# SAM9X75D1GN2 device description
Architecture: ARM926EJ-S; Family: SAM9; Series: SAM9X7
Registers are 32-bit, read-write, reset 0x0 unless marked. A register's access mark holds for its fields unless they carry their own. Offsets are from the block's base; [hi:lo] are bit positions.

## TRNG — True Random Number Generator
Instances: TRNG 0xF0030000
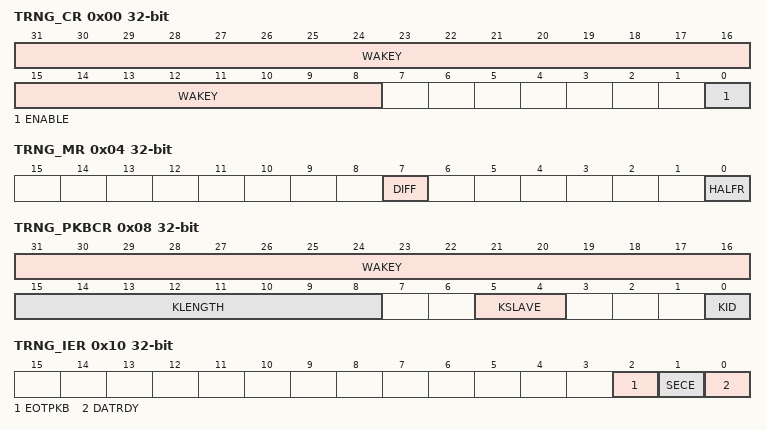
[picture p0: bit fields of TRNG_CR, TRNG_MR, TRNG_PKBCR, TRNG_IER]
0x00 TRNG_CR wo reset not defined — Control Register
  [31:8] WAKEY — Register Write Access Key
    0x524E47=PASSWD (Writing any other value in this field aborts the write operation.)
  [0] ENABLE — Enable TRNG to Provide Random Values
    0=Disables the TRNG if 0x524E47 ("RNG" in ASCII) is written in WAKEY field at the same time; 1=Enables the TRNG if 0x524E47 ("RNG" in ASCII) is written in WAKEY field at the same time
0x04 TRNG_MR — Mode Register
  [7] DIFF — Minimum Hamming Distance
    0=DISABLED (Delivers a new random sample without condition with the previous sample (unless HD=1).)
  [0] HALFR — Half Rate Enable
    0=DISABLED (Maximum stream rate provided (1 sample every 84 MCK clock cycles).); 1=ENABLED (Half maximum stream rate provided if the peripheral clock frequency is above 100 MHz (1 sample every 168 MCK clock cycles).)
0x08 TRNG_PKBCR wo reset not defined — Private Key Bus Control Register
  [31:16] WAKEY — Register Write Access Key
    0x524B=PASSWD (Writing any other value in this field aborts the write operation.)
  [15:8] KLENGTH — Key Length
  [5:4] KSLAVE — Key Bus Client
    0=TDES_ID; 1=AES_ID; 2=OTPC_ID
  [0] KID — Key ID (Must be Always Written to 0)
0x10 TRNG_IER wo reset not defined (atomic set of TRNG_IMR) — Interrupt Enable Register
  [all] fields
    0=No effect; 1=Enables the corresponding interrupt
  [2] EOTPKB — End Of Transfer on Private Key Bus Interrupt Enable
  [1] SECE — Security and/or Safety Event Interrupt Enable
  [0] DATRDY — Data Ready Interrupt Enable
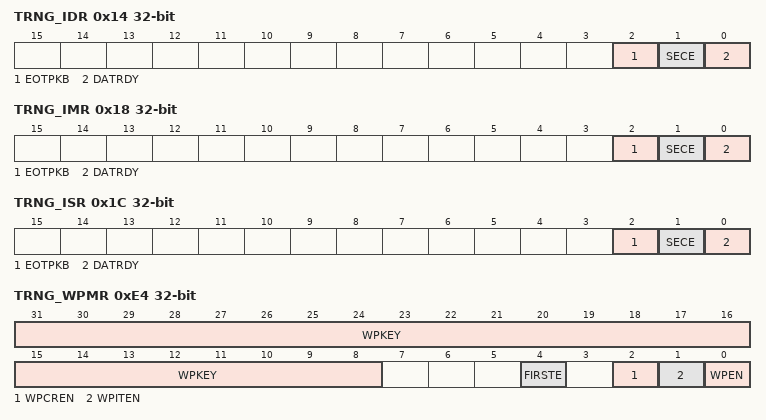
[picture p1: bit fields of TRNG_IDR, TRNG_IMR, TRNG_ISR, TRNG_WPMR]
0x14 TRNG_IDR wo reset not defined (atomic clear of TRNG_IMR) — Interrupt Disable Register
  [all] fields
    0=No effect; 1=Disables the corresponding interrupt
  [2] EOTPKB — End Of Transfer on Private Key Bus Interrupt Disable
  [1] SECE — Security and/or Safety Event Interrupt Disable
  [0] DATRDY — Data Ready Interrupt Disable
0x18 TRNG_IMR ro — Interrupt Mask Register
  [all] fields
    0=The corresponding interrupt is not enabled; 1=The corresponding interrupt is enabled
  [2] EOTPKB — End Of Transfer on Private Key Bus Interrupt Mask
  [1] SECE — Security and/or Safety Event Interrupt Mask
  [0] DATRDY — Data Ready Interrupt Mask
0x1C TRNG_ISR ro — Interrupt Status Register
  [2] EOTPKB — End Of Transfer on Private Key Bus (cleared on read)
    0=No private key bus transfer has ended since the last read of the Interrupt Status register; 1=The private key bus transfer has ended
  [1] SECE — Security and/or Safety Event (cleared on read)
    0=No safety or security event occurred since the last read of the Interrupt Status Register; 1=One or more safety or security event occurred since the last read of TRNG_ISR. For details on the event, see TRNG Write Protection Status Register.
  [0] DATRDY — Data Ready (cleared on read)
    0=Output data is not valid or TRNG is disabled; 1=New random value has been completed since the last read of TRNG_ISR
0x50 TRNG_ODATA ro — Output Data Register
  [31:0] ODATA — Output Data
0xE4 TRNG_WPMR — Write Protection Mode Register
  [31:8] WPKEY — Write Protection Key
    0x524E47=PASSWD (Writing any other value in this field aborts the write operation of bits WPEN, WPITEN and WPCREN. Always reads as 0.)
  [4] FIRSTE — First Error Report Enable
    0=The last write protection violation source is reported in TRNG_WPSR.WPVSRC and the last software control error type is reported in TRNG_WPSR.SWETYP. The TRNG_ISR.SECE flag is set at the first error occurrence within a series.; 1=Only the first write protection violation source is reported in TRNG_WPSR.WPVSRC and only the first software control error type is reported in TRNG_WPSR.SWETYP. The TRNG_ISR.SECE flag is set at the first error occurrence within a series.
  [2] WPCREN — Write Protection Control Enable
    0=Disables the write protection on control register if WPKEY corresponds to 0x524E47 ("RNG" in ASCII); 1=Enables the write protection on control register if WPKEY corresponds to 0x524E47 ("RNG" in ASCII)
  [1] WPITEN — Write Protection Interrupt Enable
    0=Disables the write protection on interrupt registers if WPKEY corresponds to 0x524E47 ("RNG" in ASCII); 1=Enables the write protection on interrupt registers if WPKEY corresponds to 0x524E47 ("RNG" in ASCII)
  [0] WPEN — Write Protection Enable
    0=Disables the write protection if WPKEY corresponds to 0x524E47 ("RNG" in ASCII); 1=Enables the write protection if WPKEY corresponds to 0x524E47 ("RNG" in ASCII)
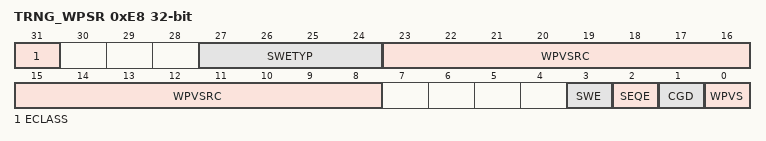
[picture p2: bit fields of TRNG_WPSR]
0xE8 TRNG_WPSR ro — Write Protection Status Register
  [31] ECLASS — Software Error Class (cleared on read)
    0=WARNING (An abnormal access that does not affect system functionality.); 1=ERROR (Reading TRNG_ODATA when TRNG was disabled or TRNG used for private key bus transfer. TRNG does not provide a random value. Writing to TRNG_PKBCR while a private key bus transfer is ongoing does not launch a new private key bus transfer.)
  [27:24] SWETYP — Software Error Type (cleared on read)
    0=READ_WO (TRNG is enabled and a write-only register has been read (Warning).); 1=WRITE_RO (TRNG is enabled and a write access has been performed on a read-only register (Warning).); 2=UNDEF_RW (Access to an undefined address.); 3=TRNG_DIS (The TRNG_ODATA register was read when TRNG was disabled or TRNG used for private key bus transfer (Error).); 4=PKB_BUSY (A write access to TRNG_PKBCR has been attempted during a private key bus transfer (Error).); 5=LOCK_ERR (A write access to TRNG_WPMR has been attempted when one of the write protection bits is already locked and its corresponding lock control bit is set and the corresponding write protection bit is cleared which looks like an unlock tentative (Warning).)
  [23:8] WPVSRC — Write Protection Violation Source (cleared on read)
  [3] SWE — Software Control Error (cleared on read)
    0=No software error has occurred since the last read of TRNG_WPSR; 1=A software error has occurred since the last read of TRNG_WPSR. The field SWETYP details the type of software error; the associated incorrect software access is reported in the field WPVSRC (if WPVS=0).
  [2] SEQE — Internal Sequencer Error (cleared on read)
    0=No peripheral internal sequencer error has occurred since the last read of TRNG_WPSR; 1=A peripheral internal sequencer error has occurred since the last read of TRNG_WPSR. This flag is set under abnormal operating conditions.
  [1] CGD — Clock Glitch Detected (cleared on read)
    0=The clock monitoring circuitry has not been corrupted since the last read of TRNG_WPSR. Under normal operating conditions, this bit is always cleared.; 1=The clock monitoring circuitry has been corrupted since the last read of TRNG_WPSR. This flag is set in case of abnormal clock signal waveform (glitch).
  [0] WPVS — Write Protection Violation Status (cleared on read)
    0=No write protection violation has occurred since the last read of TRNG_WPSR; 1=A write protection violation has occurred since the last read of TRNG_WPSR. If this violation is an unauthorized attempt to write a protected register, the associated violation is reported into field WPVSRC.
